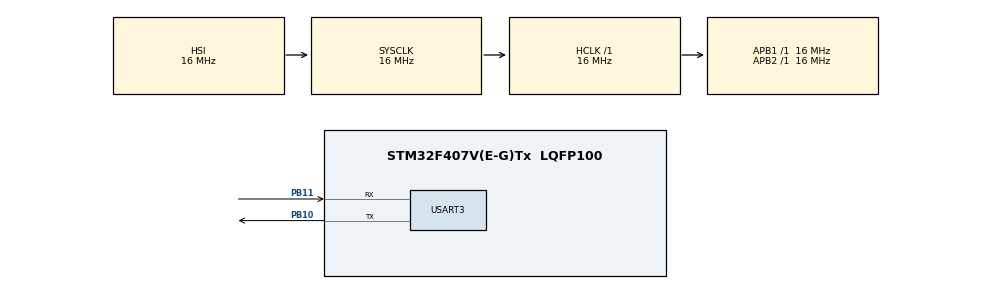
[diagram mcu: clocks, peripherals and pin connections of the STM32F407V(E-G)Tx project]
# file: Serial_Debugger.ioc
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Dma.Request0=USART3_RX
Dma.USART3_RX.0.Direction=DMA_PERIPH_TO_MEMORY
Dma.USART3_RX.0.FIFOMode=DMA_FIFOMODE_DISABLE
Dma.USART3_RX.0.Instance=DMA1_Stream1
Dma.USART3_RX.0.MemDataAlignment=DMA_MDATAALIGN_BYTE
Dma.USART3_RX.0.MemInc=DMA_MINC_ENABLE
Dma.USART3_RX.0.Mode=DMA_CIRCULAR
Dma.USART3_RX.0.PeriphDataAlignment=DMA_PDATAALIGN_BYTE
Dma.USART3_RX.0.PeriphInc=DMA_PINC_DISABLE
Dma.USART3_RX.0.Priority=DMA_PRIORITY_LOW
Mcu.Family=STM32F4
Mcu.Name=STM32F407V(E-G)Tx
Mcu.Package=LQFP100
NVIC.DMA1_Stream1_IRQn=true\:0\:0\:false\:false\:true\:false\:true\:true
NVIC.PriorityGroup=NVIC_PRIORITYGROUP_4
NVIC.USART3_IRQn=true\:0\:0\:false\:false\:true\:true\:true\:true
PB10.Mode=Asynchronous
PB10.Signal=USART3_TX
PB11.Mode=Asynchronous
PB11.Signal=USART3_RX
ProjectManager.HeapSize=0x200
ProjectManager.StackSize=0x400
ProjectManager.TargetToolchain=MDK-ARM V5
RCC.48MHZClocksFreq_Value=48000000
RCC.AHBFreq_Value=16000000
RCC.APB1Freq_Value=16000000
RCC.APB1TimFreq_Value=16000000
RCC.APB2Freq_Value=16000000
RCC.APB2TimFreq_Value=16000000
RCC.CortexFreq_Value=16000000
RCC.HCLKFreq_Value=16000000
RCC.HSE_VALUE=25000000
RCC.HSI_VALUE=16000000
RCC.LSE_VALUE=32768
RCC.SYSCLKFreq_VALUE=16000000
RCC.VCOOutputFreq_Value=192000000
USART3.VirtualMode=VM_ASYNC
board=custom

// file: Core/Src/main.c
/* USER CODE BEGIN Header */
/**
  ******************************************************************************
  * @file           : main.c
  * @brief          : Main program body
  ******************************************************************************
  * @attention
  *
  * Copyright (c) 2022 STMicroelectronics.
  * All rights reserved.
  *
  * This software is licensed under terms that can be found in the LICENSE file
  * in the root directory of this software component.
  * If no LICENSE file comes with this software, it is provided AS-IS.
  *
  ******************************************************************************
  */
/* USER CODE END Header */
#include "main.h"

/* USER CODE BEGIN Includes */
#include "string.h"
/* USER CODE END Includes */

 UART_HandleTypeDef huart3;
DMA_HandleTypeDef hdma_usart3_rx;

/* USER CODE BEGIN PV */
int POC = 0;
int Flo = 1000;
int Moi = 70;
int Sir = 0;

char txBuffer[100];
char rxBuffer[100];
char buffer[100];

char sirTerima;
char pocTerima;
char moiTerima[10];
char floTerima[10];
/* USER CODE END PV */

void SystemClock_Config(void);
static void MX_GPIO_Init(void);
static void MX_DMA_Init(void);
static void MX_USART3_UART_Init(void);

int main(void)
{

  /* MCU Configuration--------------------------------------------------------*/

  /* Reset of all peripherals, Initializes the Flash interface and the Systick. */
  HAL_Init();

  /* Configure the system clock */
  SystemClock_Config();

  /* Initialize all configured peripherals */
  MX_GPIO_Init();
  MX_DMA_Init();
  MX_USART3_UART_Init();

  /* Infinite loop */
  while (1)
  {
		HAL_UART_Receive_DMA(&huart3, (uint8_t*)rxBuffer, 6);

		POC = (int)pocTerima;
		Flo = atoi(floTerima);
		Moi = atoi(moiTerima);
		Sir = (int)sirTerima;

		int digitP = sprintf(buffer, "%d", POC);
		int digitF = sprintf(buffer, "%d", Flo);
		int digitM = sprintf(buffer, "%d", Moi);
		int digitS = sprintf(buffer, "%d", Sir);

		sprintf(txBuffer,"AP%d%dF%d%dM%d%dS%d%dB", digitP, POC, digitF, Flo, digitM, Moi, digitS, Sir);
		HAL_UART_Transmit(&huart3,(uint8_t*)txBuffer,strlen(txBuffer),1000);
		HAL_Delay(100);
  }
}

void SystemClock_Config(void)
{
  RCC_OscInitTypeDef RCC_OscInitStruct = {0};
  RCC_ClkInitTypeDef RCC_ClkInitStruct = {0};

  /** Configure the main internal regulator output voltage
  */
  __HAL_RCC_PWR_CLK_ENABLE();
  __HAL_PWR_VOLTAGESCALING_CONFIG(PWR_REGULATOR_VOLTAGE_SCALE1);

  /** Initializes the RCC Oscillators according to the specified parameters
  * in the RCC_OscInitTypeDef structure.
  */
  RCC_OscInitStruct.OscillatorType = RCC_OSCILLATORTYPE_HSI;
  RCC_OscInitStruct.HSIState = RCC_HSI_ON;
  RCC_OscInitStruct.HSICalibrationValue = RCC_HSICALIBRATION_DEFAULT;
  RCC_OscInitStruct.PLL.PLLState = RCC_PLL_NONE;
  if (HAL_RCC_OscConfig(&RCC_OscInitStruct) != HAL_OK)
  {
    Error_Handler();
  }

  /** Initializes the CPU, AHB and APB buses clocks
  */
  RCC_ClkInitStruct.ClockType = RCC_CLOCKTYPE_HCLK|RCC_CLOCKTYPE_SYSCLK
                              |RCC_CLOCKTYPE_PCLK1|RCC_CLOCKTYPE_PCLK2;
  RCC_ClkInitStruct.SYSCLKSource = RCC_SYSCLKSOURCE_HSI;
  RCC_ClkInitStruct.AHBCLKDivider = RCC_SYSCLK_DIV1;
  RCC_ClkInitStruct.APB1CLKDivider = RCC_HCLK_DIV1;
  RCC_ClkInitStruct.APB2CLKDivider = RCC_HCLK_DIV1;

  if (HAL_RCC_ClockConfig(&RCC_ClkInitStruct, FLASH_LATENCY_0) != HAL_OK)
  {
    Error_Handler();
  }
}

static void MX_USART3_UART_Init(void)
{

  huart3.Instance = USART3;
  huart3.Init.BaudRate = 115200;
  huart3.Init.WordLength = UART_WORDLENGTH_8B;
  huart3.Init.StopBits = UART_STOPBITS_1;
  huart3.Init.Parity = UART_PARITY_NONE;
  huart3.Init.Mode = UART_MODE_TX_RX;
  huart3.Init.HwFlowCtl = UART_HWCONTROL_NONE;
  huart3.Init.OverSampling = UART_OVERSAMPLING_16;
  if (HAL_UART_Init(&huart3) != HAL_OK)
  {
    Error_Handler();
  }

}

static void MX_DMA_Init(void)
{

  /* DMA controller clock enable */
  __HAL_RCC_DMA1_CLK_ENABLE();

  /* DMA interrupt init */
  /* DMA1_Stream1_IRQn interrupt configuration */
  HAL_NVIC_SetPriority(DMA1_Stream1_IRQn, 0, 0);
  HAL_NVIC_EnableIRQ(DMA1_Stream1_IRQn);

}

static void MX_GPIO_Init(void)
{

  /* GPIO Ports Clock Enable */
  __HAL_RCC_GPIOB_CLK_ENABLE();

}

/* USER CODE BEGIN 4 */
void HAL_UART_RxCpltCallback(UART_HandleTypeDef *huart){
	if(huart->Instance == USART3){
		//int lenRX = sprintf(buffer, "%s", rxBuffer);
		//if (lenRX > 2){
			//sprintf(floTerima, rxBuffer[lenRX-1]);
			if(rxBuffer[0] == 'F') {
				//for(int i=1; i<lenRX-1; i++)
				//{
					//floTerima += rxBuffer[i];
				//}
				memmove(rxBuffer, rxBuffer+1, strlen(rxBuffer));
				sprintf(floTerima, "%s" ,rxBuffer);

			}
			if(rxBuffer[0] == 'M') {
				//for(int i=1; i<lenRX-1; i++)
				//{
					//moiTerima += rxBuffer[i];
				//}
				memmove(rxBuffer, rxBuffer+1, strlen(rxBuffer));
				sprintf(moiTerima, "%s" , rxBuffer);
			}
		//}
		if(rxBuffer[0] == 'P' && rxBuffer[2] == 'S') {
			pocTerima = rxBuffer[1];
		}
		if(rxBuffer[0] == 'B' && rxBuffer[2] == 'S') {
			sirTerima = rxBuffer[1];
		}
	}
}
/* USER CODE END 4 */

void Error_Handler(void)
{
  __disable_irq();
  while (1)
  {
  }
}
